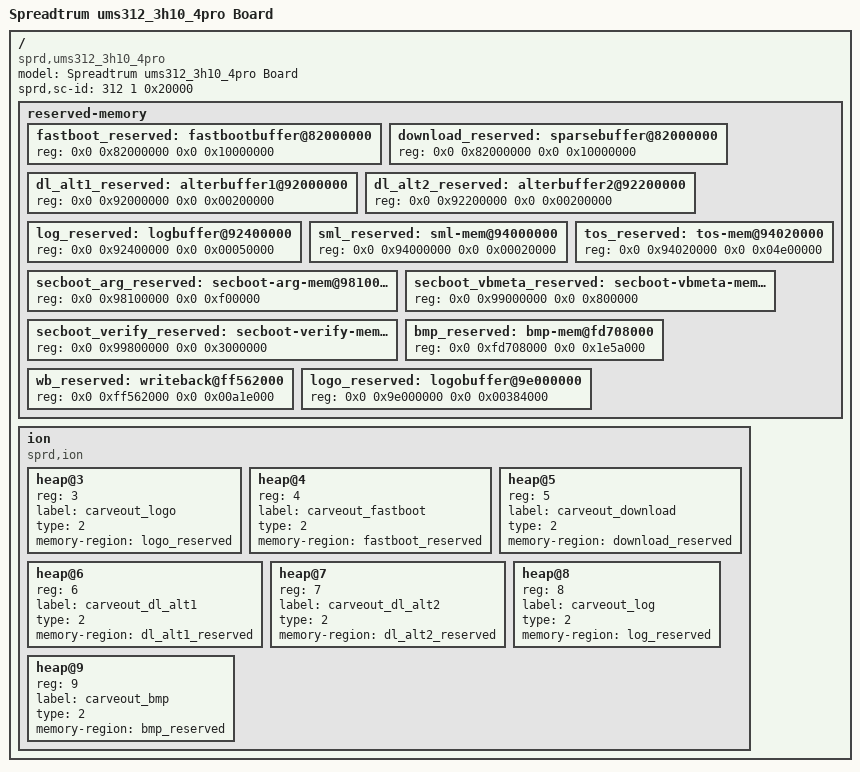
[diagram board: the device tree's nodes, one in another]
/*
 * Spreadtrum SP9860g board DTS file
 *
 * Copyright (C) 2016, Spreadtrum Communications Inc.
 *
 * This file is licensed under a dual GPLv2 or X11 license.
 */

/dts-v1/;

/ {
	model = "Spreadtrum ums312_3h10_4pro Board";

	compatible = "sprd,ums312_3h10_4pro";

	sprd,sc-id = <312 1 0x20000>;

	reserved-memory {
		#address-cells = <2>;
		#size-cells = <2>;
		ranges;

		fastboot_reserved: fastbootbuffer@82000000{
			reg = <0x0 0x82000000 0x0 0x10000000>;
		};

		download_reserved: sparsebuffer@82000000{
			reg = <0x0 0x82000000 0x0 0x10000000>;
		};

		dl_alt1_reserved: alterbuffer1@92000000{
			reg = <0x0 0x92000000 0x0 0x00200000>;
		};

		dl_alt2_reserved: alterbuffer2@92200000{
			reg = <0x0 0x92200000 0x0 0x00200000>;
		};

		log_reserved: logbuffer@92400000{
			reg = <0x0 0x92400000 0x0 0x00050000>;
		};

		/* must be 4K aligned */
		sml_reserved: sml-mem@94000000{
			reg = <0x0 0x94000000 0x0 0x00020000>;
		};

		tos_reserved: tos-mem@94020000{
			reg = <0x0 0x94020000 0x0 0x04e00000>;
		};

		secboot_arg_reserved: secboot-arg-mem@98100000{
			reg = <0x0 0x98100000 0x0 0xf00000>;
		};

		secboot_vbmeta_reserved: secboot-vbmeta-mem@99000000{
			reg = <0x0 0x99000000 0x0 0x800000>;
		};

		secboot_verify_reserved: secboot-verify-mem@99800000{
			reg = <0x0 0x99800000 0x0 0x3000000>;
		};

		bmp_reserved: bmp-mem@fd708000 {
			reg = <0x0 0xfd708000 0x0 0x1e5a000>;
		};

		wb_reserved: writeback@ff562000 {
			reg = <0x0 0xff562000 0x0 0x00a1e000>;
		};

		logo_reserved: logobuffer@9e000000 {
			reg = <0x0 0x9e000000 0x0 0x00384000>;
		};
	};

	ion {
		compatible = "sprd,ion";
		#address-cells = <1>;
		#size-cells = <0>;

		heap@3 {
			reg = <3>;
			label = "carveout_logo";
			type = <2>;
			memory-region = <&logo_reserved>;
		};

		heap@4 {
			reg = <4>;
			label = "carveout_fastboot";
			type = <2>;
			memory-region = <&fastboot_reserved>;
		};

		heap@5 {
			reg = <5>;
			label = "carveout_download";
			type = <2>;
			memory-region = <&download_reserved>;
		};

		heap@6 {
			reg = <6>;
			label = "carveout_dl_alt1";
			type = <2>;
			memory-region = <&dl_alt1_reserved>;
		};

		heap@7 {
			reg = <7>;
			label = "carveout_dl_alt2";
			type = <2>;
			memory-region = <&dl_alt2_reserved>;
		};

		heap@8 {
			reg = <8>;
			label = "carveout_log";
			type = <2>;
			memory-region = <&log_reserved>;
		};

		heap@9 {
			reg = <9>;
			label = "carveout_bmp";
			type = <2>;
			memory-region = <&bmp_reserved>;
		};
	};

};
